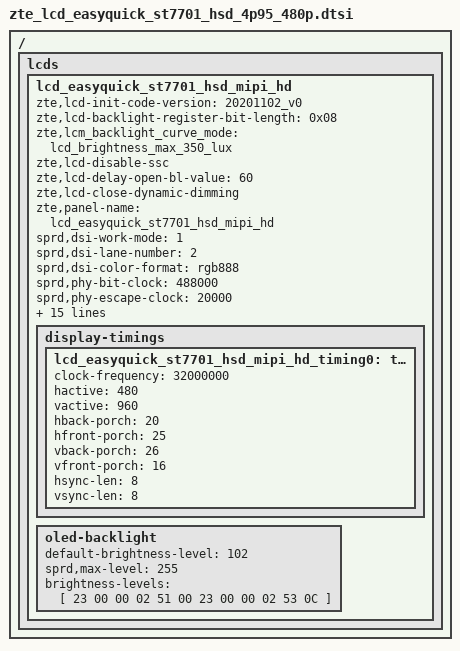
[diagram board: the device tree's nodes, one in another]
/ { lcds {
	lcd_easyquick_st7701_hsd_mipi_hd: lcd_easyquick_st7701_hsd_mipi_hd {
		zte,lcd-init-code-version = "20201102_v0";
		zte,lcd-backlight-register-bit-length = <0x08>;
		zte,lcm_backlight_curve_mode = "lcd_brightness_max_350_lux";
		zte,lcd-disable-ssc;
		zte,lcd-delay-open-bl-value = <60>;
		zte,lcd-close-dynamic-dimming;
		zte,panel-name = "lcd_easyquick_st7701_hsd_mipi_hd";


		sprd,dsi-work-mode = <1>; /* video burst mode*/
		sprd,dsi-lane-number = <2>;
		sprd,dsi-color-format = "rgb888";

		sprd,phy-bit-clock = <488000>;	/* kbps */
		sprd,phy-escape-clock = <20000>;/* kHz */

		sprd,width-mm = <56160>;
		sprd,height-mm = <112320>;

		sprd,esd-check-enable = <1>;/* 0:close , 1:open */
		sprd,esd-check-mode = <1>;/* 0:REG ,1:TE  */
		sprd,esd-check-period = <1000>;
		sprd,esd-check-register = <0x0A>;
		sprd,esd-check-value = <0x9C>;
		sprd,reset-on-sequence = <1 5>, <0 5>, <1 120>;
		sprd,reset-off-sequence = <0 0>, <0 0>, <0 120>;

		sprd,initial-command = [
			39 00 00 06 FF 77 01 00 00 13
			39 00 00 02 EF 08
			39 00 00 03 E8 00 0E
			39 0a 00 03 E8 00 0C
			39 00 00 03 E8 00 00
			39 00 00 06 FF 77 01 00 00 10
			39 00 00 03 C0 77 00
			39 00 00 03 C1 0E 02
			39 00 00 03 C2 07 02
			39 00 00 02 CC 38
			39 00 00 02 BB 00
			39 00 00 02 CA 11
			39 00 00 02 BC 01
			39 00 00 11 B0 00 03 0B 0E 15 0D 0A 09 09 1F 0A 15 10 8C 11 D4
			39 00 00 11 B1 00 03 09 10 15 0C 06 0A 09 1F 08 18 14 97 1F D4
			39 00 00 06 FF 77 01 00 00 11
			39 00 00 02 B0 42
			39 00 00 02 B1 5B
			39 00 00 02 B2 87
			39 00 00 02 B3 80
			39 00 00 02 B5 4E
			39 00 00 02 B7 87
			39 00 00 02 B8 20
			39 00 00 02 BB 03
			39 00 00 02 C1 78
			39 00 00 02 C2 78
			39 64 00 02 D0 88
			39 00 00 04 E0 00 00 02
			39 00 00 0C E1 07 8C 09 8C 06 8C 08 8C 00 44 44
			39 00 00 0E E2 00 00 00 00 00 00 00 00 00 00 00 00 00
			39 00 00 05 E3 00 00 33 33
			39 00 00 03 E4 44 44
			39 00 00 11 E5 0F CA 8C 8C 11 CA 8C 8C 0B CA 8C 8C 0D CA 8C 8C
			39 00 00 05 E6 00 00 33 33
			39 00 00 03 E7 44 44
			39 00 00 11 E8 0E CA 8C 8C 10 CA 8C 8C 0A CA 8C 8C 0C CA 8C 8C
			39 00 00 08 EB 02 00 00 00 00 00 00
			39 00 00 11 ED AB 89 76 54 01 FF FF FF FF FF FF 10 45 67 98 BA
			39 00 00 06 FF 77 01 00 00 00
			39 00 00 02 35 00
			39 00 00 02 51 00
			39 00 00 02 53 0C
			39 00 00 02 55 01
			23 78 00 02 11 00
			23 14 00 02 29 00
			];
		sprd,sleep-in-command = [
			39 05 00 02 53 00
			39 20 00 02 51 00
			13 0A 00 01 28
			13 78 00 01 10
			39 00 00 07 FF 77 01 00 00 11 80
			39 00 00 06 FF 77 01 00 00 91
			];
		sprd,sleep-out-command = [
			13 78 00 01 11
			13 64 00 01 29
			];

		display-timings {
			lcd_easyquick_st7701_hsd_mipi_hd_timing0: timing0 {
			clock-frequency = <32000000>;
			hactive = <480>;
			vactive = <960>;
			hback-porch = <20>;
			hfront-porch = <25>;
			vback-porch = <26>;
			vfront-porch = <16>;
			hsync-len = <8>;
			vsync-len = <8>;
			};
		};
		oled-backlight {
			default-brightness-level = <102>;
			sprd,max-level = <255>;
			brightness-levels = [
				23 00 00 02 51 00
				23 00 00 02 53 0C
			];
		};
	};
};};

